# AC33Mx128 register map
Vendor: ABOV Semiconductor Co., Ltd.; File version: 0.6
CPU: CM3 r1p0, little endian, no MPU, no FPU, 3 interrupt priority bits
Registers are 32-bit, read-write, reset 0x0 unless marked. A register's access mark holds for its fields unless they carry their own. Offsets are from the block's base; [hi:lo] are bit positions; {n}, {i} and the like mark numbered series.

## MP0 — MOTOR PULSE-WIDTH-MODULATOR
Base 0x40004000
Same registers: MP1 0x40005000
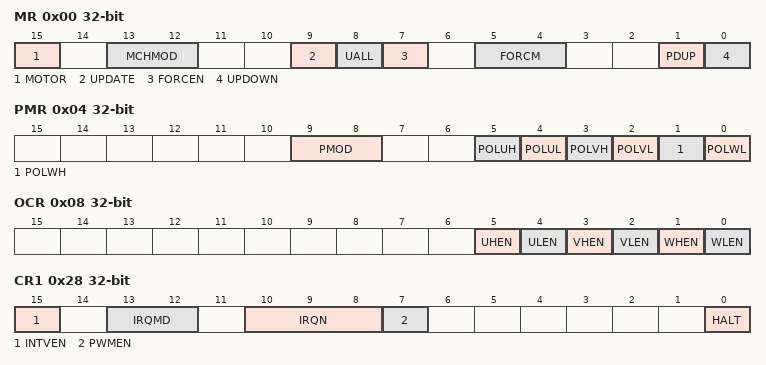
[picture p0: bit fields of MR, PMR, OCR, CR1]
0x00 MR — MPWM Mode Register
  [15] MOTOR — Normal/Motor mode
  [13:12] MCHMOD — Motor control channel mode
  [9] UPDATE
  [8] UALL — Update all duty register
  [7] FORCEN — force mode
  [5:4] FORCM — force mode
  [1] PDUP — period duty update at ..
  [0] UPDOWN — PWM counter mode
0x04 PMR — MPWM Port Mode Register
  [9:8] PMOD — PWM pulse mode
  [5] POLUH — Polarity of UH PIN
  [4] POLUL — Polarity of UL PIN
  [3] POLVH — Polarity of UH PIN
  [2] POLVL — Polarity of UL PIN
  [1] POLWH — Polarity of UH PIN
  [0] POLWL — Polarity of UL PIN
0x08 OCR — MPWM Output Control Register
  [5] UHEN — PWM UH output control in force mode
  [4] ULEN — PWM UL output control in force mode
  [3] VHEN — PWM VH output control in force mode
  [2] VLEN — PWM VL output control in force mode
  [1] WHEN — PWM WH output control in force mode
  [0] WLEN — PWM WL output control in force mode
0x0C PRD — MPWM Period Register
  [15:0] PERIOD — PWM period
0x10 DUH — MPWM Duty UH Register
  [15:0] DUTY — duty of UH output
0x14 DVH — MPWM Duty VH Register
  [15:0] DUTY — duty of VH data
0x18 DWH — MPWM Duty WH Register
  [15:0] DUTY — duty of WH output
0x1C DUL — MPWM Duty UL Register
  [15:0] DUTY — duty of UL output
0x20 DVL — MPWM Duty UL Register
  [15:0] DUTY — duty of VL output
0x24 DWL — MPWM Duty WL Register
  [15:0] DUTY — duty of WL output
0x28 CR1 — MPWM Control Register 1
  [15] INTVEN — IRQ intervel mode
  [13:12] IRQMD — IRQ mode
  [10:8] IRQN — IRQ intervel Number
  [7] PWMEN — PWM enable
  [0] HALT — PWM HALT
0x2C CR2 — MPWM Control Register 2
  [0] PSTART — PWM start
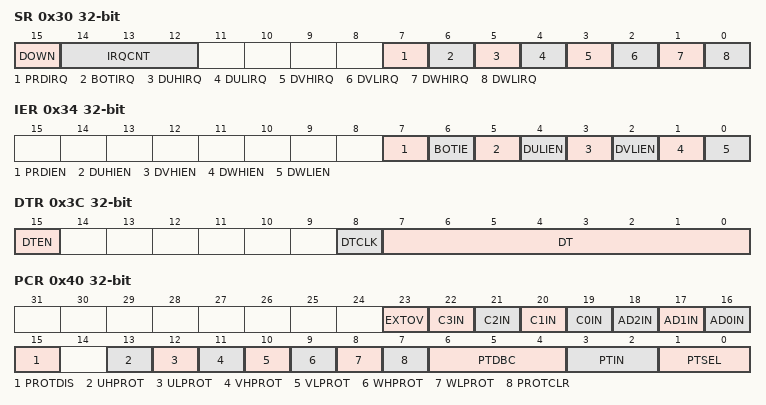
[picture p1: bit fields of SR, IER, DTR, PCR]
0x30 SR — MPWM Status Register
  [15] DOWN — PWM count up/down
  [14:12] IRQCNT — PWM count number of period match
  [7] PRDIRQ — PWM period interrupt flag
  [6] BOTIRQ — PWM bottom interrupt flag
  [5] DUHIRQ — duty UH interrupt flag
  [4] DULIRQ — duty UL interrupt flag
  [3] DVHIRQ — duty VH interrupt flag
  [2] DVLIRQ — duty VL interrupt flag
  [1] DWHIRQ — duty WH interrupt flag
  [0] DWLIRQ — duty WL interrupt flag
0x34 IER — MPWM Interrupt Enable Register
  [7] PRDIEN — Period interrupt enable
  [6] BOTIE — bottom interrupt enable
  [5] DUHIEN — duty UH interrupt enable
  [4] DULIEN — duty UL interrupt enable
  [3] DVHIEN — duty VH interrupt enable
  [2] DVLIEN — duty VL interrupt enable
  [1] DWHIEN — duty WH interrupt enable
  [0] DWLIEN — duty WL interrupt enable
0x38 CNT — MPWM Counter Register
  [15:0] CNT — pwm counter value
0x3C DTR — MPWM Dead Time Register
  [15] DTEN — dead time Enable
  [8] DTCLK — dead time clk select
  [7:0] DT — dead time value
0x40 PCR — MPWM Protection control Register
  [23] EXTOV — EXT ov pin input
  [n+19] C{n}IN (n=0..3) — comparator {n} output
  [18] AD2IN — ADC2 Comparator output
  [17] AD1IN — ADC1 Comparator output
  [16] AD0IN — ADC0 Comparator output
  [15] PROTDIS — Protect mode disable
  [13] UHPROT — UH protection output
  [12] ULPROT — UL protection output
  [11] VHPROT — VH protection output
  [10] VLPROT — VL protection output
  [9] WHPROT — WH protection output
  [8] WLPROT — WL protection output
  [7] PROTCLR — protection clear
  [6:4] PTDBC — protection signal debounce
  [3:2] PTIN — Protection Input
  [1:0] PTSEL — protection mode sel
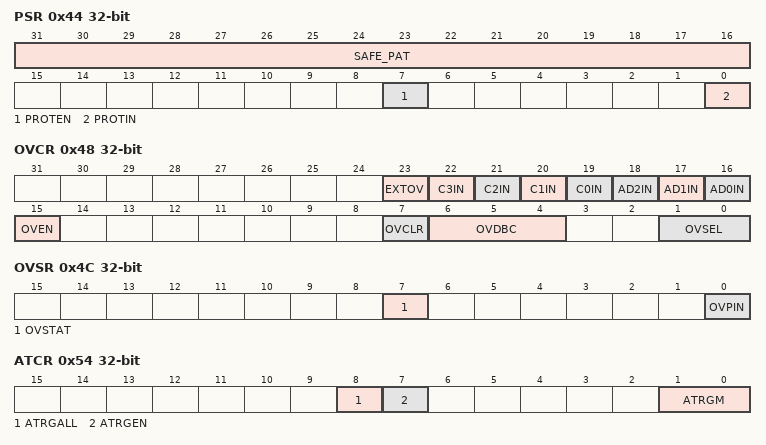
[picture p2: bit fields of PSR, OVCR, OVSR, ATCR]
0x44 PSR — MPWM Protection Status Register
  [31:16] SAFE_PAT — lock safety pattern to set or reset protection
  [7] PROTEN — Protection mode enable status
  [0] PROTIN — Protection Input status
0x48 OVCR — MPWM Over Voltage control Register
  [23] EXTOV — ext OV pin input
  [n+19] C{n}IN (n=0..3) — comparator {n} output
  [18] AD2IN — ADC2 Comparator output
  [17] AD1IN — ADC1 Comparator output
  [16] AD0IN — ADC0 Comparator output
  [15] OVEN — over voltage protection mode
  [7] OVCLR — OV protection clear
  [6:4] OVDBC — OV voltage protection signal debounce
  [1:0] OVSEL — OV voltage proection mode select
0x4C OVSR — MPWM Over Voltage Status Register
  [7] OVSTAT — Over voltage protection mode status
  [0] OVPIN — Over voltage protection input status
0x54 ATCR — MPWM ADC Trigger Control Register
  [8] ATRGALL — ADC Trigger register 0 match event
  [7] ATRGEN — ADC Trigger Mode Enable
  [1:0] ATRGM — ADC Trigger Mode
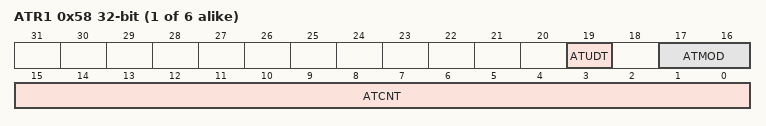
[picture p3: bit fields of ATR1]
{0x54+4i} ATR{i} (i=1..6) — MPWMn ADC Trigger Counter {i} Register
  [19] ATUDT — Trigger register update mode
  [17:16] ATMOD — ADC Trigger mode register
  [15:0] ATCNT — ADC Trigger counter
